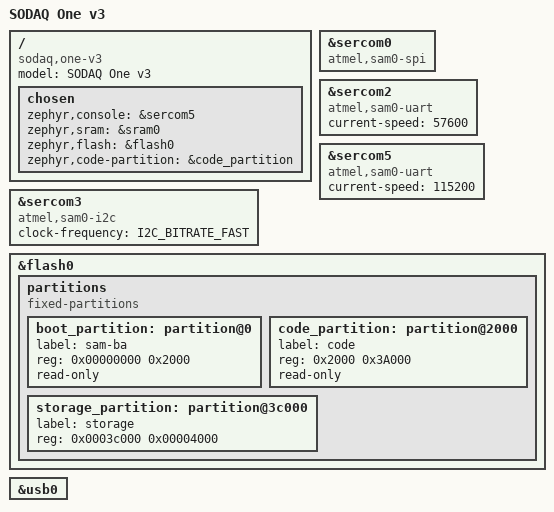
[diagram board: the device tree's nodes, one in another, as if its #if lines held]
/*
 * Copyright (c) 2018 Henrik Brix Andersen <henrik@brixandersen.dk>
 *
 * SPDX-License-Identifier: Apache-2.0
 */

/dts-v1/;
#include <atmel/samd21.dtsi>

/ {
	model = "SODAQ One v3";
	compatible = "sodaq,one-v3", "atmel,samd21g18a",
			"atmel,samd21";

	chosen {
		zephyr,console = &sercom5;
		zephyr,sram = &sram0;
		zephyr,flash = &flash0;
		zephyr,code-partition = &code_partition;
	};
};

&sercom0 {
	status = "ok";
	compatible = "atmel,sam0-spi";
	#address-cells = <1>;
	#size-cells = <0>;
};

&sercom2 {
	status = "ok";
	compatible = "atmel,sam0-uart";
	current-speed = <57600>;
};

&sercom3 {
	status = "ok";
	compatible = "atmel,sam0-i2c";
	clock-frequency = <I2C_BITRATE_FAST>;	
};

&sercom5 {
	status = "ok";
	compatible = "atmel,sam0-uart";
	current-speed = <115200>;
};

&flash0 {
	partitions {
		compatible = "fixed-partitions";
		#address-cells = <1>;
		#size-cells = <1>;

		boot_partition: partition@0 {
			label = "sam-ba";
			reg = <0x00000000 0x2000>;
			read-only;
		};

		code_partition: partition@2000 {
			label = "code";
			reg = <0x2000 0x3A000>;
			read-only;
		};

		/*
		 * The final 16 KiB is reserved for the application
		 * and is used by NFFS if enabled.
		 */

#if defined(CONFIG_FS_FLASH_STORAGE_PARTITION)
		storage_partition: partition@3c000 {
			label = "storage";
			reg = <0x0003c000 0x00004000>;
		};
#endif
	};
};

&usb0 {
	status = "ok";
};
